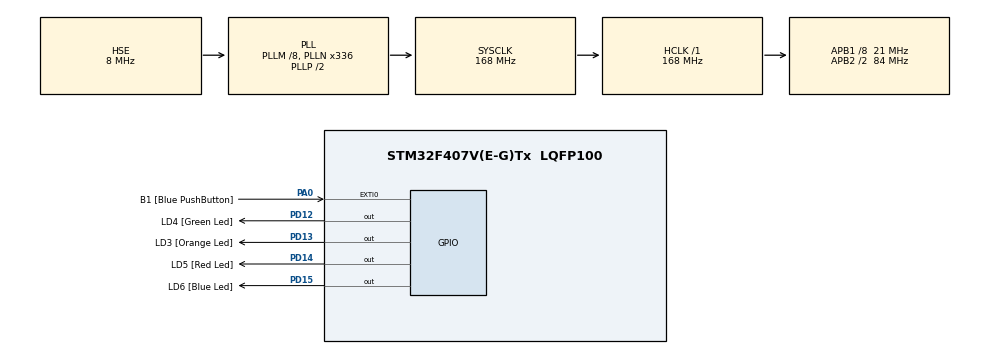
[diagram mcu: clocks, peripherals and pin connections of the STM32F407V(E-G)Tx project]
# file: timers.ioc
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Mcu.Family=STM32F4
Mcu.Name=STM32F407V(E-G)Tx
Mcu.Package=LQFP100
NVIC.PriorityGroup=NVIC_PRIORITYGROUP_0
NVIC.TIM6_DAC_IRQn=true\:0\:0\:false\:false\:true\:true\:true
PA0-WKUP.GPIO_Label=B1 [Blue PushButton]
PA0-WKUP.GPIO_ModeDefaultEXTI=GPIO_MODE_EVT_RISING
PA0-WKUP.GPIO_PuPd=GPIO_NOPULL
PA0-WKUP.Signal=GPXTI0
PD12.GPIO_Label=LD4 [Green Led]
PD12.GPIO_PuPd=GPIO_NOPULL
PD12.GPIO_Speed=GPIO_SPEED_FREQ_LOW
PD12.Signal=GPIO_Output
PD13.GPIO_Label=LD3 [Orange Led]
PD13.GPIO_PuPd=GPIO_NOPULL
PD13.GPIO_Speed=GPIO_SPEED_FREQ_LOW
PD13.Signal=GPIO_Output
PD14.GPIO_Label=LD5 [Red Led]
PD14.GPIO_PuPd=GPIO_NOPULL
PD14.GPIO_Speed=GPIO_SPEED_FREQ_LOW
PD14.Signal=GPIO_Output
PD15.GPIO_Label=LD6 [Blue Led]
PD15.GPIO_PuPd=GPIO_NOPULL
PD15.GPIO_Speed=GPIO_SPEED_FREQ_LOW
PD15.Signal=GPIO_Output
PH0-OSC_IN.GPIO_Label=PH0-OSC_IN
PH0-OSC_IN.Mode=HSE-External-Oscillator
PH0-OSC_IN.Signal=RCC_OSC_IN
PH1-OSC_OUT.GPIO_Label=PH1-OSC_OUT
PH1-OSC_OUT.Mode=HSE-External-Oscillator
PH1-OSC_OUT.Signal=RCC_OSC_OUT
ProjectManager.HeapSize=0x200
ProjectManager.StackSize=0x400
ProjectManager.TargetToolchain=MDK-ARM V5
RCC.48MHZClocksFreq_Value=48000000
RCC.AHBFreq_Value=168000000
RCC.APB1CLKDivider=RCC_HCLK_DIV8
RCC.APB1Freq_Value=21000000
RCC.APB1TimFreq_Value=42000000
RCC.APB2CLKDivider=RCC_HCLK_DIV2
RCC.APB2Freq_Value=84000000
RCC.APB2TimFreq_Value=168000000
RCC.CortexFreq_Value=168000000
RCC.HCLKFreq_Value=168000000
RCC.HSE_VALUE=8000000
RCC.HSI_VALUE=16000000
RCC.PLLM=8
RCC.PLLN=336
RCC.PLLQ=7
RCC.PLLSourceVirtual=RCC_PLLSOURCE_HSE
RCC.SYSCLKFreq_VALUE=168000000
RCC.SYSCLKSource=RCC_SYSCLKSOURCE_PLLCLK
RCC.VCOOutputFreq_Value=336000000
TIM6.AutoReloadPreload=TIM_AUTORELOAD_PRELOAD_DISABLE
TIM6.Period=499
TIM6.Prescaler=20999
TIM6.TIM_MasterOutputTrigger=TIM_TRGO_UPDATE
VP_TIM6_VS_ClockSourceINT.Mode=Enable_Timer
board=STM32F4DISCOVERY

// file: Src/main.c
/* USER CODE BEGIN Header */
/**
  ******************************************************************************
  * @file           : main.c
  * @brief          : Main program body
  ******************************************************************************
  * @attention
  *
  * <h2><center>&copy; Copyright (c) 2019 STMicroelectronics.
  * All rights reserved.</center></h2>
  *
  * This software component is licensed by ST under Ultimate Liberty license
  * SLA0044, the "License"; You may not use this file except in compliance with
  * the License. You may obtain a copy of the License at:
  *                             www.st.com/SLA0044
  *
  ******************************************************************************
  */
/* USER CODE END Header */

#include "main.h"
#include "tim.h"
#include "gpio.h"

/* USER CODE BEGIN PV */
uint8_t tim6_counter = 0;
/* USER CODE END PV */

void SystemClock_Config(void);

int main(void)
{

  /* MCU Configuration--------------------------------------------------------*/

  /* Reset of all peripherals, Initializes the Flash interface and the Systick. */
  HAL_Init();

  /* Configure the system clock */
  SystemClock_Config();

  /* Initialize all configured peripherals */
  MX_GPIO_Init();
  MX_TIM6_Init();

  /* Infinite loop */
  /* USER CODE BEGIN WHILE */
  while (1)
  {
    if(HAL_GPIO_ReadPin(B1_GPIO_Port, B1_Pin) == GPIO_PIN_SET)
    {
      HAL_TIM_Base_Start(&htim6);
      HAL_TIM_Base_Start_IT(&htim6);
    }
    else
    {
      tim6_counter = 0;
      HAL_TIM_Base_Stop(&htim6);
      HAL_TIM_Base_Stop_IT(&htim6);
      HAL_GPIO_WritePin(GPIOD, GPIO_PIN_12 | GPIO_PIN_13 | GPIO_PIN_14 | GPIO_PIN_15, GPIO_PIN_RESET);
    }
    /* USER CODE END WHILE */

  }
}

void SystemClock_Config(void)
{
  RCC_OscInitTypeDef RCC_OscInitStruct = {0};
  RCC_ClkInitTypeDef RCC_ClkInitStruct = {0};

  /** Configure the main internal regulator output voltage
  */
  __HAL_RCC_PWR_CLK_ENABLE();
  __HAL_PWR_VOLTAGESCALING_CONFIG(PWR_REGULATOR_VOLTAGE_SCALE1);
  /** Initializes the CPU, AHB and APB busses clocks
  */
  RCC_OscInitStruct.OscillatorType = RCC_OSCILLATORTYPE_HSE;
  RCC_OscInitStruct.HSEState = RCC_HSE_ON;
  RCC_OscInitStruct.PLL.PLLState = RCC_PLL_ON;
  RCC_OscInitStruct.PLL.PLLSource = RCC_PLLSOURCE_HSE;
  RCC_OscInitStruct.PLL.PLLM = 8;
  RCC_OscInitStruct.PLL.PLLN = 336;
  RCC_OscInitStruct.PLL.PLLP = RCC_PLLP_DIV2;
  RCC_OscInitStruct.PLL.PLLQ = 7;
  if (HAL_RCC_OscConfig(&RCC_OscInitStruct) != HAL_OK)
  {
    Error_Handler();
  }
  /** Initializes the CPU, AHB and APB busses clocks
  */
  RCC_ClkInitStruct.ClockType = RCC_CLOCKTYPE_HCLK|RCC_CLOCKTYPE_SYSCLK
                              |RCC_CLOCKTYPE_PCLK1|RCC_CLOCKTYPE_PCLK2;
  RCC_ClkInitStruct.SYSCLKSource = RCC_SYSCLKSOURCE_PLLCLK;
  RCC_ClkInitStruct.AHBCLKDivider = RCC_SYSCLK_DIV1;
  RCC_ClkInitStruct.APB1CLKDivider = RCC_HCLK_DIV8;
  RCC_ClkInitStruct.APB2CLKDivider = RCC_HCLK_DIV2;

  if (HAL_RCC_ClockConfig(&RCC_ClkInitStruct, FLASH_LATENCY_5) != HAL_OK)
  {
    Error_Handler();
  }
}

void Error_Handler(void)
{
}

/************************ (C) COPYRIGHT STMicroelectronics *****END OF FILE****/
